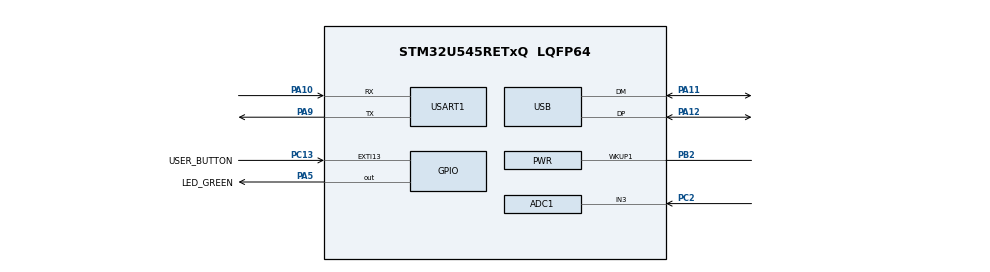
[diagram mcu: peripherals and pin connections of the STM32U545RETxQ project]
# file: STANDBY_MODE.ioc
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ADC1.Channel-0\#ChannelRegularConversion=ADC_CHANNEL_3
ADC1.MonitoredBy-0\#ChannelRegularConversion=__NULL
ADC1.NbrOfConversionFlag=1
ADC1.OffsetNumber-0\#ChannelRegularConversion=ADC_OFFSET_NONE
ADC1.Rank-0\#ChannelRegularConversion=1
ADC1.SamplingTime-0\#ChannelRegularConversion=ADC_SAMPLETIME_5CYCLE
ADC1.master=1
CORTEX_M33_NS.userName=CORTEX_M33
Mcu.Family=STM32U5
Mcu.Name=STM32U545RETxQ
Mcu.Package=LQFP64
NVIC.PWR_S3WU_IRQn=true\:0\:0\:false\:false\:true\:true\:true\:true
NVIC.PriorityGroup=NVIC_PRIORITYGROUP_4
NVIC.RTC_IRQn=true\:0\:0\:false\:false\:true\:true\:true\:true
PA10.Mode=Asynchronous
PA10.Signal=USART1_RX
PA11.Mode=Host
PA11.Signal=USB_DM
PA12.Mode=Host
PA12.Signal=USB_DP
PA13\ (JTMS/SWDIO).Mode=Trace_Asynchronous_SW
PA13\ (JTMS/SWDIO).Signal=DEBUG_JTMS-SWDIO
PA14\ (JTCK/SWCLK).Mode=Trace_Asynchronous_SW
PA14\ (JTCK/SWCLK).Signal=DEBUG_JTCK-SWCLK
PA5.GPIO_Label=LED_GREEN
PA5.GPIO_PuPd=GPIO_PULLUP
PA5.GPIO_Speed=GPIO_SPEED_FREQ_HIGH
PA5.Signal=GPIO_Output
PA9.Mode=Asynchronous
PA9.Signal=USART1_TX
PB2.Mode=WakeUp1
PB2.Signal=PWR_WKUP1
PB3\ (JTDO/TRACESWO).Mode=Trace_Asynchronous_SW
PB3\ (JTDO/TRACESWO).Signal=DEBUG_JTDO-SWO
PC13.GPIO_Label=USER_BUTTON
PC13.GPIO_ModeDefaultEXTI=GPIO_MODE_IT_FALLING
PC13.Signal=GPXTI13
PC14-OSC32_IN\ (PC14).Mode=LSE-External-Oscillator
PC14-OSC32_IN\ (PC14).Signal=RCC_OSC32_IN
PC15-OSC32_OUT\ (PC15).Mode=LSE-External-Oscillator
PC15-OSC32_OUT\ (PC15).Signal=RCC_OSC32_OUT
PC2.Mode=IN3-Single-Ended
PC2.Signal=ADC1_IN3
PWR.PowerMode=PWR_SMPS_SUPPLY
ProjectManager.HeapSize=0x200
ProjectManager.StackSize=0x400
ProjectManager.TargetToolchain=STM32CubeIDE
RCC.ADCFreq_Value=16000000
RCC.DACCLockSelectionVirtual=RCC_DAC1CLKSOURCE_LSI
RCC.DACCLockSelectionVirtualString=RCC_DAC1CLKSOURCE_LSI
RCC.EPOD_VALUE=4000000
RCC.HSE_VALUE=16000000
RCC.HSI48_VALUE=48000000
RCC.HSI_VALUE=16000000
RCC.LSIDIV_VALUE=32000
RCC.MSI_VALUE=4000000
RCC.USBFreq_Value=48000000
RCC.VCOOutputFreq_Value=516000000
RTC.Alarm-Alarm\ A=RTC_ALARM_A
RTC.AlarmMaskSeconds-Alarm\ A=RTC_ALARMMASK_SECONDS
RTC.Hours_A-Alarm\ A=0
RTC.Minutes_A-Alarm\ A=0
RTC.Seconds_A-Alarm\ A=30
USART1.VirtualMode-Asynchronous=VM_ASYNC
VP_ICACHE_VS_ICACHE.Mode=DirectMappedCache
VP_LPBAMQUEUE_VS_QUEUE.Mode=QUEUEMODE
VP_LPBAM_VS_SIG1.Mode=SmartRun
VP_LPBAM_VS_SIG4.Mode=LPDMA1
VP_MEMORYMAP_VS_MEMORYMAP.Mode=CurAppReg
VP_PWR_VS_DBSignals.Mode=DisableDeadBatterySignals
VP_PWR_VS_LPOM.Mode=PowerOptimisation
VP_PWR_VS_SECSignals.Mode=Security/Privilege
VP_PWR_Vdda.Mode=isolationVdda
VP_RTC_VS_RTC_Activate.Mode=RTC_Enabled
VP_RTC_VS_RTC_Alarm_A_Intern.Mode=Alarm A
VP_RTC_VS_RTC_Calendar.Mode=RTC_Calendar
board=NUCLEO-U545RE-Q

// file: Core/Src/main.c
/* USER CODE BEGIN Header */
/**
  ******************************************************************************
  * @file           : main.c
  * @brief          : Main program body
  ******************************************************************************
  * @attention
  *
  * Copyright (c) 2024 STMicroelectronics.
  * All rights reserved.
  *
  * This software is licensed under terms that can be found in the LICENSE file
  * in the root directory of this software component.
  * If no LICENSE file comes with this software, it is provided AS-IS.
  *
  ******************************************************************************
  */
/* USER CODE END Header */
#include "main.h"

ADC_HandleTypeDef hadc1;

RTC_HandleTypeDef hrtc;

UART_HandleTypeDef huart1;

HCD_HandleTypeDef hhcd_USB_DRD_FS;

void SystemClock_Config(void);
static void SystemPower_Config(void);
static void MX_GPIO_Init(void);
static void MX_ADC1_Init(void);
static void MX_ICACHE_Init(void);
static void MX_USART1_UART_Init(void);
static void MX_USB_DRD_FS_HCD_Init(void);
static void MX_RTC_Init(void);

int main(void)
{

  /* MCU Configuration--------------------------------------------------------*/

  /* Reset of all peripherals, Initializes the Flash interface and the Systick. */
  HAL_Init();

  /* Configure the system clock */
  SystemClock_Config();

  /* Configure the System Power */
  SystemPower_Config();

  /* Initialize all configured peripherals */
  MX_GPIO_Init();
  MX_ADC1_Init();
  MX_ICACHE_Init();
  MX_USART1_UART_Init();
  MX_USB_DRD_FS_HCD_Init();
  MX_RTC_Init();

  /* Infinite loop */
  while (1)
  {

  }
}

void SystemClock_Config(void)
{
  RCC_OscInitTypeDef RCC_OscInitStruct = {0};
  RCC_ClkInitTypeDef RCC_ClkInitStruct = {0};

  /** Configure the main internal regulator output voltage
  */
  if (HAL_PWREx_ControlVoltageScaling(PWR_REGULATOR_VOLTAGE_SCALE3) != HAL_OK)
  {
    Error_Handler();
  }

  /** Initializes the CPU, AHB and APB buses clocks
  */
  RCC_OscInitStruct.OscillatorType = RCC_OSCILLATORTYPE_HSI48|RCC_OSCILLATORTYPE_HSI
                              |RCC_OSCILLATORTYPE_LSI|RCC_OSCILLATORTYPE_MSI;
  RCC_OscInitStruct.HSIState = RCC_HSI_ON;
  RCC_OscInitStruct.HSI48State = RCC_HSI48_ON;
  RCC_OscInitStruct.HSICalibrationValue = RCC_HSICALIBRATION_DEFAULT;
  RCC_OscInitStruct.LSIState = RCC_LSI_ON;
  RCC_OscInitStruct.MSIState = RCC_MSI_ON;
  RCC_OscInitStruct.MSICalibrationValue = RCC_MSICALIBRATION_DEFAULT;
  RCC_OscInitStruct.MSIClockRange = RCC_MSIRANGE_4;
  RCC_OscInitStruct.LSIDiv = RCC_LSI_DIV1;
  RCC_OscInitStruct.PLL.PLLState = RCC_PLL_NONE;
  if (HAL_RCC_OscConfig(&RCC_OscInitStruct) != HAL_OK)
  {
    Error_Handler();
  }

  /** Initializes the CPU, AHB and APB buses clocks
  */
  RCC_ClkInitStruct.ClockType = RCC_CLOCKTYPE_HCLK|RCC_CLOCKTYPE_SYSCLK
                              |RCC_CLOCKTYPE_PCLK1|RCC_CLOCKTYPE_PCLK2
                              |RCC_CLOCKTYPE_PCLK3;
  RCC_ClkInitStruct.SYSCLKSource = RCC_SYSCLKSOURCE_MSI;
  RCC_ClkInitStruct.AHBCLKDivider = RCC_SYSCLK_DIV1;
  RCC_ClkInitStruct.APB1CLKDivider = RCC_HCLK_DIV1;
  RCC_ClkInitStruct.APB2CLKDivider = RCC_HCLK_DIV1;
  RCC_ClkInitStruct.APB3CLKDivider = RCC_HCLK_DIV1;

  if (HAL_RCC_ClockConfig(&RCC_ClkInitStruct, FLASH_LATENCY_0) != HAL_OK)
  {
    Error_Handler();
  }
}

/**
  * @brief Power Configuration
  * @retval None
  */
static void SystemPower_Config(void)
{

  /*
   * Switch to SMPS regulator instead of LDO
   */
  if (HAL_PWREx_ConfigSupply(PWR_SMPS_SUPPLY) != HAL_OK)
  {
    Error_Handler();
  }
  /* PWR_S3WU_IRQn interrupt configuration */
  HAL_NVIC_SetPriority(PWR_S3WU_IRQn, 0, 0);
  HAL_NVIC_EnableIRQ(PWR_S3WU_IRQn);
}

static void MX_ADC1_Init(void)
{

  ADC_ChannelConfTypeDef sConfig = {0};

  /** Common config
  */
  hadc1.Instance = ADC1;
  hadc1.Init.ClockPrescaler = ADC_CLOCK_ASYNC_DIV1;
  hadc1.Init.Resolution = ADC_RESOLUTION_14B;
  hadc1.Init.GainCompensation = 0;
  hadc1.Init.DataAlign = ADC_DATAALIGN_RIGHT;
  hadc1.Init.ScanConvMode = ADC_SCAN_DISABLE;
  hadc1.Init.EOCSelection = ADC_EOC_SINGLE_CONV;
  hadc1.Init.LowPowerAutoWait = DISABLE;
  hadc1.Init.ContinuousConvMode = DISABLE;
  hadc1.Init.NbrOfConversion = 1;
  hadc1.Init.DiscontinuousConvMode = DISABLE;
  hadc1.Init.ExternalTrigConv = ADC_SOFTWARE_START;
  hadc1.Init.ExternalTrigConvEdge = ADC_EXTERNALTRIGCONVEDGE_NONE;
  hadc1.Init.DMAContinuousRequests = DISABLE;
  hadc1.Init.TriggerFrequencyMode = ADC_TRIGGER_FREQ_HIGH;
  hadc1.Init.Overrun = ADC_OVR_DATA_PRESERVED;
  hadc1.Init.LeftBitShift = ADC_LEFTBITSHIFT_NONE;
  hadc1.Init.ConversionDataManagement = ADC_CONVERSIONDATA_DR;
  hadc1.Init.OversamplingMode = DISABLE;
  if (HAL_ADC_Init(&hadc1) != HAL_OK)
  {
    Error_Handler();
  }

  /** Configure Regular Channel
  */
  sConfig.Channel = ADC_CHANNEL_3;
  sConfig.Rank = ADC_REGULAR_RANK_1;
  sConfig.SamplingTime = ADC_SAMPLETIME_5CYCLE;
  sConfig.SingleDiff = ADC_SINGLE_ENDED;
  sConfig.OffsetNumber = ADC_OFFSET_NONE;
  sConfig.Offset = 0;
  if (HAL_ADC_ConfigChannel(&hadc1, &sConfig) != HAL_OK)
  {
    Error_Handler();
  }

}

static void MX_ICACHE_Init(void)
{

  /** Enable instruction cache in 1-way (direct mapped cache)
  */
  if (HAL_ICACHE_ConfigAssociativityMode(ICACHE_1WAY) != HAL_OK)
  {
    Error_Handler();
  }
  if (HAL_ICACHE_Enable() != HAL_OK)
  {
    Error_Handler();
  }

}

static void MX_RTC_Init(void)
{

  RTC_PrivilegeStateTypeDef privilegeState = {0};
  RTC_TimeTypeDef sTime = {0};
  RTC_DateTypeDef sDate = {0};
  RTC_AlarmTypeDef sAlarm = {0};

  /** Initialize RTC Only
  */
  hrtc.Instance = RTC;
  hrtc.Init.HourFormat = RTC_HOURFORMAT_24;
  hrtc.Init.AsynchPrediv = 127;
  hrtc.Init.SynchPrediv = 255;
  hrtc.Init.OutPut = RTC_OUTPUT_DISABLE;
  hrtc.Init.OutPutRemap = RTC_OUTPUT_REMAP_NONE;
  hrtc.Init.OutPutPolarity = RTC_OUTPUT_POLARITY_HIGH;
  hrtc.Init.OutPutType = RTC_OUTPUT_TYPE_OPENDRAIN;
  hrtc.Init.OutPutPullUp = RTC_OUTPUT_PULLUP_NONE;
  hrtc.Init.BinMode = RTC_BINARY_NONE;
  if (HAL_RTC_Init(&hrtc) != HAL_OK)
  {
    Error_Handler();
  }
  privilegeState.rtcPrivilegeFull = RTC_PRIVILEGE_FULL_NO;
  privilegeState.backupRegisterPrivZone = RTC_PRIVILEGE_BKUP_ZONE_NONE;
  privilegeState.backupRegisterStartZone2 = RTC_BKP_DR0;
  privilegeState.backupRegisterStartZone3 = RTC_BKP_DR0;
  if (HAL_RTCEx_PrivilegeModeSet(&hrtc, &privilegeState) != HAL_OK)
  {
    Error_Handler();
  }

  /** Initialize RTC and set the Time and Date
  */
  sTime.Hours = 0x0;
  sTime.Minutes = 0x0;
  sTime.Seconds = 0x0;
  sTime.DayLightSaving = RTC_DAYLIGHTSAVING_NONE;
  sTime.StoreOperation = RTC_STOREOPERATION_RESET;
  if (HAL_RTC_SetTime(&hrtc, &sTime, RTC_FORMAT_BCD) != HAL_OK)
  {
    Error_Handler();
  }
  sDate.WeekDay = RTC_WEEKDAY_MONDAY;
  sDate.Month = RTC_MONTH_JANUARY;
  sDate.Date = 0x1;
  sDate.Year = 0x0;

  if (HAL_RTC_SetDate(&hrtc, &sDate, RTC_FORMAT_BCD) != HAL_OK)
  {
    Error_Handler();
  }

  /** Enable the Alarm A
  */
  sAlarm.AlarmTime.Hours = 0x0;
  sAlarm.AlarmTime.Minutes = 0x0;
  sAlarm.AlarmTime.Seconds = 0x30;
  sAlarm.AlarmTime.SubSeconds = 0x0;
  sAlarm.AlarmMask = RTC_ALARMMASK_SECONDS;
  sAlarm.AlarmSubSecondMask = RTC_ALARMSUBSECONDMASK_ALL;
  sAlarm.AlarmDateWeekDaySel = RTC_ALARMDATEWEEKDAYSEL_DATE;
  sAlarm.AlarmDateWeekDay = 0x1;
  sAlarm.Alarm = RTC_ALARM_A;
  if (HAL_RTC_SetAlarm_IT(&hrtc, &sAlarm, RTC_FORMAT_BCD) != HAL_OK)
  {
    Error_Handler();
  }

}

static void MX_USART1_UART_Init(void)
{

  huart1.Instance = USART1;
  huart1.Init.BaudRate = 115200;
  huart1.Init.WordLength = UART_WORDLENGTH_8B;
  huart1.Init.StopBits = UART_STOPBITS_1;
  huart1.Init.Parity = UART_PARITY_NONE;
  huart1.Init.Mode = UART_MODE_TX_RX;
  huart1.Init.HwFlowCtl = UART_HWCONTROL_NONE;
  huart1.Init.OverSampling = UART_OVERSAMPLING_16;
  huart1.Init.OneBitSampling = UART_ONE_BIT_SAMPLE_DISABLE;
  huart1.Init.ClockPrescaler = UART_PRESCALER_DIV1;
  huart1.AdvancedInit.AdvFeatureInit = UART_ADVFEATURE_NO_INIT;
  if (HAL_UART_Init(&huart1) != HAL_OK)
  {
    Error_Handler();
  }
  if (HAL_UARTEx_SetTxFifoThreshold(&huart1, UART_TXFIFO_THRESHOLD_1_8) != HAL_OK)
  {
    Error_Handler();
  }
  if (HAL_UARTEx_SetRxFifoThreshold(&huart1, UART_RXFIFO_THRESHOLD_1_8) != HAL_OK)
  {
    Error_Handler();
  }
  if (HAL_UARTEx_DisableFifoMode(&huart1) != HAL_OK)
  {
    Error_Handler();
  }

}

static void MX_USB_DRD_FS_HCD_Init(void)
{

  hhcd_USB_DRD_FS.Instance = USB_DRD_FS;
  hhcd_USB_DRD_FS.Init.dev_endpoints = 8;
  hhcd_USB_DRD_FS.Init.Host_channels = 8;
  hhcd_USB_DRD_FS.Init.speed = HCD_SPEED_FULL;
  hhcd_USB_DRD_FS.Init.phy_itface = HCD_PHY_EMBEDDED;
  hhcd_USB_DRD_FS.Init.Sof_enable = DISABLE;
  hhcd_USB_DRD_FS.Init.low_power_enable = DISABLE;
  hhcd_USB_DRD_FS.Init.vbus_sensing_enable = DISABLE;
  hhcd_USB_DRD_FS.Init.bulk_doublebuffer_enable = DISABLE;
  hhcd_USB_DRD_FS.Init.iso_singlebuffer_enable = DISABLE;
  if (HAL_HCD_Init(&hhcd_USB_DRD_FS) != HAL_OK)
  {
    Error_Handler();
  }

}

static void MX_GPIO_Init(void)
{
  GPIO_InitTypeDef GPIO_InitStruct = {0};

  /* GPIO Ports Clock Enable */
  __HAL_RCC_GPIOC_CLK_ENABLE();
  __HAL_RCC_GPIOA_CLK_ENABLE();
  __HAL_RCC_GPIOB_CLK_ENABLE();

  /*Configure GPIO pin Output Level */
  HAL_GPIO_WritePin(LED_GREEN_GPIO_Port, LED_GREEN_Pin, GPIO_PIN_RESET);

  /*Configure GPIO pin : USER_BUTTON_Pin */
  GPIO_InitStruct.Pin = USER_BUTTON_Pin;
  GPIO_InitStruct.Mode = GPIO_MODE_IT_FALLING;
  GPIO_InitStruct.Pull = GPIO_NOPULL;
  HAL_GPIO_Init(USER_BUTTON_GPIO_Port, &GPIO_InitStruct);

  /*Configure GPIO pin : LED_GREEN_Pin */
  GPIO_InitStruct.Pin = LED_GREEN_Pin;
  GPIO_InitStruct.Mode = GPIO_MODE_OUTPUT_PP;
  GPIO_InitStruct.Pull = GPIO_PULLUP;
  GPIO_InitStruct.Speed = GPIO_SPEED_FREQ_HIGH;
  HAL_GPIO_Init(LED_GREEN_GPIO_Port, &GPIO_InitStruct);

}

/* USER CODE BEGIN 4 */
void HAL_RTC_AlarmAEventCallback(RTC_HandleTypeDef *hrtc)
{

}
/* USER CODE END 4 */

void Error_Handler(void)
{
  __disable_irq();
  while (1)
  {
  }
}
